# f29h85x_memss_misci_regs register map
Vendor: Texas Instruments
Peripheral module from a debugger description file (folder HSM).
Registers are 32-bit, read-write, no defined reset value unless marked. A register's access mark holds for its fields unless they carry their own. Offsets are as the file gives them; lines under a group give offsets from that group; [hi:lo] are bit positions; {n}, {i} and the like mark numbered series; 'fields as' and 'values as' point back to an identical list; <NAME> marks a mode.

## MEMSS_MISCI_REGS — MEMSS MISCI Registers
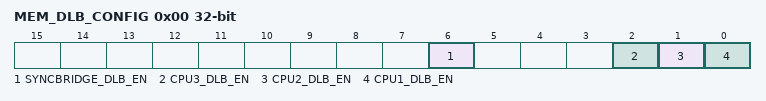
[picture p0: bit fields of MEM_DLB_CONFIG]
0x00 MEM_DLB_CONFIG — Dataline buffer enable
  [6] SYNCBRIDGE_DLB_EN — Sync Bridge Dataline buffer Enable
  [2] CPU3_DLB_EN — CPU3 Data line buffer Enable
  [1] CPU2_DLB_EN — CPU2 Data line buffer Enable
  [0] CPU1_DLB_EN — CPU1 Data line buffer Enable
0x04 MEM_DLB_CONFIG_LOCK — Temporary Lock for DLB Configuration Register
  [0] MEM_DLB_CONFIG — Temporary Lock
0x08 MEM_DLB_CONFIG_COMMIT — Permament Lock for DLB Configuration Register
  [0] MEM_DLB_CONFIG_LOCK — Permanent Commit
0x10 PERI_MEM_TEST_LOCK — Peripheral Memory Test Lock Register
  [0] PERI_MEM_TEST_CONTROL — PERI_MEM_TEST_CONTROL Lock bit
0x14 PERI_MEM_TEST_CONTROL — Peripheral Memory Test control Register
  [5] EtherCAT_MEM_FORCE_ERROR — Force Parity Error on EtherCAT RAM
0x1FC PARITY_TEST — Enabling the parity test feature
  [3:0] TESTEN — Parity test enable
